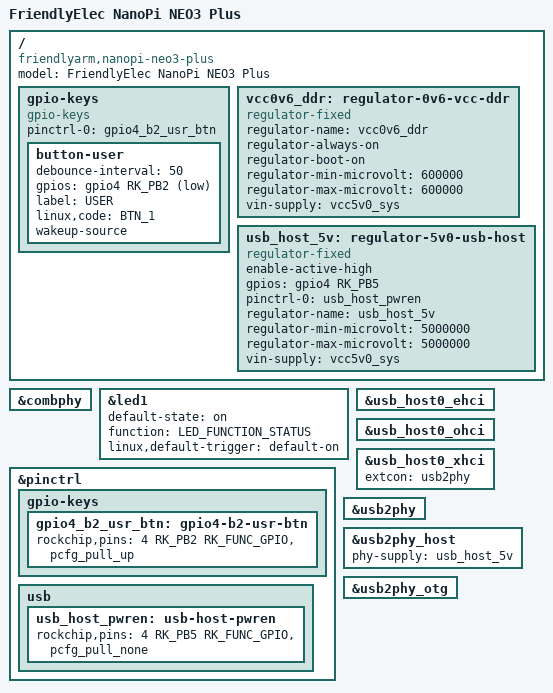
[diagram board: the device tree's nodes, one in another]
// SPDX-License-Identifier: (GPL-2.0+ OR MIT)

/dts-v1/;

#include "rk3528-nanopi.dtsi"

/ {
	model = "FriendlyElec NanoPi NEO3 Plus";
	compatible = "friendlyarm,nanopi-neo3-plus", "rockchip,rk3528";

	gpio-keys {
		compatible = "gpio-keys";
		pinctrl-names = "default";
		pinctrl-0 = <&gpio4_b2_usr_btn>;

		button-user {
			debounce-interval = <50>;
			gpios = <&gpio4 RK_PB2 GPIO_ACTIVE_LOW>;
			label = "USER";
			linux,code = <BTN_1>;
			wakeup-source;
		};
	};

	vcc0v6_ddr: regulator-0v6-vcc-ddr {
		compatible = "regulator-fixed";
		regulator-name = "vcc0v6_ddr";
		regulator-always-on;
		regulator-boot-on;
		regulator-min-microvolt = <600000>;
		regulator-max-microvolt = <600000>;
		vin-supply = <&vcc5v0_sys>;
	};

	usb_host_5v: regulator-5v0-usb-host {
		compatible = "regulator-fixed";
		enable-active-high;
		gpios = <&gpio4 RK_PB5 GPIO_ACTIVE_HIGH>;
		pinctrl-names = "default";
		pinctrl-0 = <&usb_host_pwren>;
		regulator-name = "usb_host_5v";
		regulator-min-microvolt = <5000000>;
		regulator-max-microvolt = <5000000>;
		vin-supply = <&vcc5v0_sys>;
	};
};

&combphy {
	status = "okay";
};

&led1 {
	default-state = "on";
	function = LED_FUNCTION_STATUS;
	linux,default-trigger = "default-on";
};

&pinctrl {
	gpio-keys {
		gpio4_b2_usr_btn: gpio4-b2-usr-btn {
			rockchip,pins = <4 RK_PB2 RK_FUNC_GPIO &pcfg_pull_up>;
		};
	};

	usb {
		usb_host_pwren: usb-host-pwren {
			rockchip,pins = <4 RK_PB5 RK_FUNC_GPIO &pcfg_pull_none>;
		};
	};
};

&usb_host0_ehci {
	status = "okay";
};

&usb_host0_ohci {
	status = "okay";
};

&usb_host0_xhci {
	extcon = <&usb2phy>;
	status = "okay";
};

&usb2phy {
	status = "okay";
};

&usb2phy_host {
	phy-supply = <&usb_host_5v>;
	status = "okay";
};

&usb2phy_otg {
	status = "okay";
};
